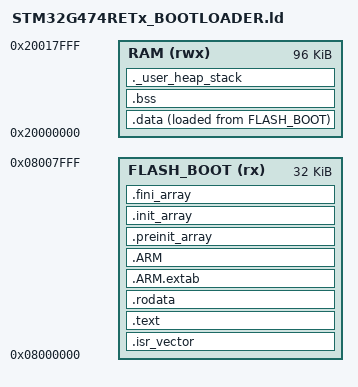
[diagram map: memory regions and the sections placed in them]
/*
 * =============================================================================
 * STM32G474RETx_BOOTLOADER.ld - Robot Controller Board bootloader linker script
 * PROJECT: HYDRA-UMC (Robot Controller Board firmware, Tier 1 - STM32G474RET6)
 * AUTHOR: JuanenRac (Electro Hobby 3D) - electrohobby3d@gmail.com
 * LICENSE: GPL-3.0 - see repo root LICENSE
 *
 * See ../STM32G474RETx_APP.ld's own header comment for the full flash
 * partitioning this bootloader slot is one piece of - PROPOSED, modeled on
 * URTC's own proven bootloader/app split, not yet verified against real
 * hardware.
 */

MEMORY
{
  FLASH_BOOT (rx) : ORIGIN = 0x08000000, LENGTH = 32K
  RAM (rwx)        : ORIGIN = 0x20000000, LENGTH = 96K
}

ENTRY(Reset_Handler)

_estack = ORIGIN(RAM) + LENGTH(RAM);
_Min_Heap_Size = 0x200;
_Min_Stack_Size = 0x400;

SECTIONS
{
  .isr_vector :
  {
    . = ALIGN(4);
    KEEP(*(.isr_vector))
    . = ALIGN(4);
  } >FLASH_BOOT

  .text :
  {
    . = ALIGN(4);
    *(.text)
    *(.text*)
    *(.glue_7)
    *(.glue_7t)
    *(.eh_frame)
    KEEP (*(.init))
    KEEP (*(.fini))
    . = ALIGN(4);
    _etext = .;
  } >FLASH_BOOT

  .rodata :
  {
    . = ALIGN(4);
    *(.rodata)
    *(.rodata*)
    . = ALIGN(4);
  } >FLASH_BOOT

  .ARM.extab : { *(.ARM.extab* .gnu.linkonce.armextab.*) } >FLASH_BOOT
  .ARM : { __exidx_start = .; *(.ARM.exidx*) __exidx_end = .; } >FLASH_BOOT
  .preinit_array : { PROVIDE_HIDDEN (__preinit_array_start = .); KEEP (*(.preinit_array*)); PROVIDE_HIDDEN (__preinit_array_end = .); } >FLASH_BOOT
  .init_array : { PROVIDE_HIDDEN (__init_array_start = .); KEEP (*(SORT(.init_array.*))); KEEP (*(.init_array*)); PROVIDE_HIDDEN (__init_array_end = .); } >FLASH_BOOT
  .fini_array : { PROVIDE_HIDDEN (__fini_array_start = .); KEEP (*(SORT(.fini_array.*))); KEEP (*(.fini_array*)); PROVIDE_HIDDEN (__fini_array_end = .); } >FLASH_BOOT

  _sidata = LOADADDR(.data);

  .data :
  {
    . = ALIGN(4);
    _sdata = .;
    *(.data)
    *(.data*)
    . = ALIGN(4);
    _edata = .;
  } >RAM AT> FLASH_BOOT

  . = ALIGN(4);
  .bss :
  {
    _sbss = .;
    __bss_start__ = _sbss;
    *(.bss)
    *(.bss*)
    *(COMMON)
    . = ALIGN(4);
    _ebss = .;
    __bss_end__ = _ebss;
  } >RAM

  ._user_heap_stack :
  {
    . = ALIGN(8);
    PROVIDE ( end = . );
    PROVIDE ( _end = . );
    . = . + _Min_Heap_Size;
    . = . + _Min_Stack_Size;
    . = ALIGN(8);
  } >RAM

  /DISCARD/ : { libc.a ( * ) libm.a ( * ) libgcc.a ( * ) }
  .ARM.attributes 0 : { *(.ARM.attributes) }
}
